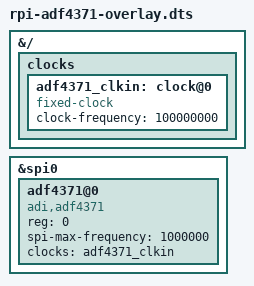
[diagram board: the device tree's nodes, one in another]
// SPDX-License-Identifier: GPL-2.0
/dts-v1/;
/plugin/;

&{/} {
	clocks {
		adf4371_clkin: clock@0 {
			#clock-cells = <0>;
			compatible = "fixed-clock";
			clock-frequency = <100000000>; // 100MHz
		};
	};
};

&spi0 {
	#address-cells = <1>;
	#size-cells = <0>;
	status = "okay";

	adf4371@0 {
		compatible = "adi,adf4371";
		reg = <0>;
		spi-max-frequency = <1000000>;
		clocks = <&adf4371_clkin>;
		clock-names = "clkin";
	};
};
